# nrf7140_application register map
Vendor: Nordic Semiconductor; Series: nRF71; File version: 1
CPU: CM33 r0p4, little endian, MPU, FPU, 3 interrupt priority bits, 480 interrupts, 8 SAU regions
Registers are 32-bit, read-write, reset 0x0 unless marked. A register's access mark holds for its fields unless they carry their own. Offsets are from the block's base; [hi:lo] are bit positions; lines under a group give offsets from that group; {n}, {i} and the like mark numbered series; 'fields as' and 'values as' point back to an identical list.

## GLOBAL_SDCARD_NS — SD-Card and eMMC 0
Base 0x4F8C9000
Same registers: GLOBAL_SDCARD_S 0x5F8C9000
0x500 ENABLE — Enable the SDCARD peripheral
  [0] ENABLE — Enable or disable SDCARD
    0=Disabled (Disable SDCARD); 1=Enabled (Enable SDCARD)
0x600 CORE group — Unspecified
  0x00 SDMASAR — This register is used to configure a 32-bit Block Count or an SDMA System Address based on the Host Version 4 Enable bit in the Host Control 2 register. This register is applicable for both SD and eMMC modes.
    [31:0] BLOCKCNTSDMASA — 32-bit Block Count (SDMA System Address)
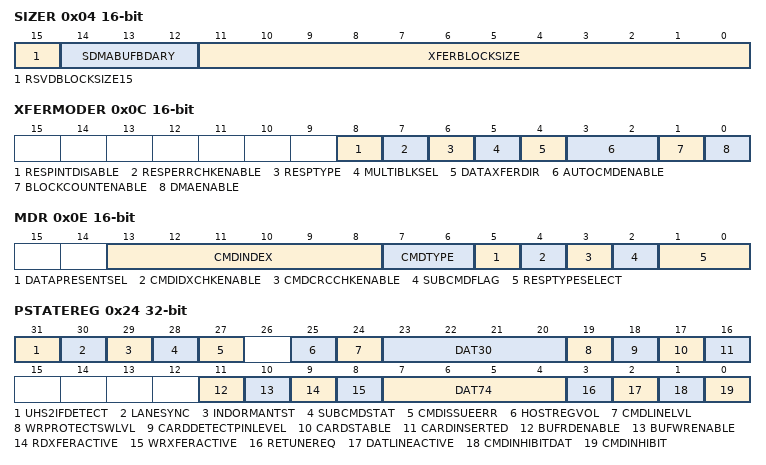
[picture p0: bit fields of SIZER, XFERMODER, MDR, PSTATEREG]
  0x04 SIZER 16-bit — This register is used to configure an SDMA buffer boundary and the number of bytes in a data block. This register is applicable for both SD and eMMC modes.
    [15] RSVDBLOCKSIZE15 ro — This bit of the BLOCKSIZE_R register is reserved. It always returns 0.
    [14:12] SDMABUFBDARY — SDMA Buffer Boundary
      0=BYTES4K (4K bytes SDMA Buffer Boundary); 1=BYTES8K (8K bytes SDMA Buffer Boundary); 2=BYTES16K (16K bytes SDMA Buffer Boundary); 3=BYTES32K (32K bytes SDMA Buffer Boundary); 4=BYTES64K (64K bytes SDMA Buffer Boundary); 5=BYTES128K (128K bytes SDMA Buffer Boundary); 6=BYTES256K (256K bytes SDMA Buffer Boundary); 7=BYTES512K (512K bytes SDMA Buffer Boundary)
    [11:0] XFERBLOCKSIZE — Transfer Block Size
  0x06 UNTR 16-bit — This register is used to configure the number of data blocks. This register is applicable for both SD and eMMC modes.
    [15:0] BLOCKCNT — 16-bit Block Count
  0x08 ARGUMENTR — This register is used to configure the SD/eMMC command argument.
    [31:0] ARGUMENT — Command Argument
  0x0C XFERMODER 16-bit — This register is used to control the operation of data transfers for an SD/eMMC mode. The Host driver sets this register before issuing a command that transfers data.
    [8] RESPINTDISABLE
      0=ENABLED (Response Interrupt is enabled); 1=DISABLED (Response Interrupt is disabled)
    [7] RESPERRCHKENABLE
      0=DISABLED (Response Error Check is disabled); 1=ENABLED (Response Error Check is enabled)
    [6] RESPTYPE
      0=RESPR1 (R1 (Memory)); 1=RESPR5 (R5 (SDIO))
    [5] MULTIBLKSEL
      0=SINGLE (Single Block); 1=MULTI (Multiple Block)
    [4] DATAXFERDIR
      0=WRITE (Write (Host to Card)); 1=READ (Read (Card to Host))
    [3:2] AUTOCMDENABLE — Auto Command Enable
      0=AUTOCMDDISABLED (Auto Command Disabled); 1=AUTOCMD12ENABLED; 2=AUTOCMD23ENABLED; 3=AUTOCMDAUTOSEL (Auto CMD Auto Select)
    [1] BLOCKCOUNTENABLE
      0=DISABLED; 1=ENABLED
    [0] DMAENABLE
      0=DISABLED (No data transfer or Non-DMA data transfer); 1=ENABLED (DMA Data transfer)
  0x0E MDR 16-bit — This register is used to provide the information related to a command and a response packet. This register is applicable for an SD/eMMC mode.
    [13:8] CMDINDEX — Command Index
    [7:6] CMDTYPE — Command Type
      0=NORMALCMD; 1=SUSPENDCMD; 2=RESUMECMD; 3=ABORTCMD
    [5] DATAPRESENTSEL — Data Present Select
      0=NODATA (No Data Present); 1=DATA (Data Present)
    [4] CMDIDXCHKENABLE — Command Index Check Enable
      0=DISABLED; 1=ENABLED
    [3] CMDCRCCHKENABLE — Command CRC Check Enable
      0=DISABLED; 1=ENABLED
    [2] SUBCMDFLAG — Sub Command Flag
      0=MAIN (Main Command); 1=SUB (Sub Command)
    [1:0] RESPTYPESELECT — Response Type Select
      0=NORESP (No Response); 1=RESPLEN136 (Response Length 136); 2=RESPLEN48 (Response Length 48); 3=RESPLEN48B (Response Length 48; Check Busy after response)
  0x10 RESP01R — This register stores 39-08 bits of the Response Field for an SD/eMMC mode. The response for an SD/eMMC command can be a maximum of 128 bits. These 128 bits are segregated into four 32-bit registers: RESP01_R, RESP23_R, RESP45_R and RESP67_R.
    [31:0] RESP01 ro — Command Response
  0x14 RESP23R — This register stores 71-40 bits of the Response Field for an SD/eMMC mode. This register is used to store the response from the cards. The response can be a maximum of 128 bits. These 128 bits are segregated into four 32-bit
    [31:0] RESP23 ro — Command Response
  0x18 RESP45R — This register stores 103-72 bits of the Response Field for an SD/eMMC mode. The response for SD/eMMC command can be a maximum of 128 bits. These 128 bits are segregated into four 32-bit registers: RESP01_R, RESP23_R, RESP45_R and RESP67_R.
    [31:0] RESP45 ro — Command Response
  0x1C RESP67R — This register stores 135-104 bits of the Response Field for an SD/eMMC mode. The SD/eMMC response can be a maximum of 128 bits. These 128 bits are segregated into four 32-bit registers: RESP01_R, RESP23_R, RESP45_R and RESP67_R.
    [31:0] RESP67 ro — Command Response
  0x20 UFDATAR — This register is used to access the packet buffer. This register is applicable for an SD/eMMC/UHS-II mode.
    [31:0] BUFDATA — Buffer Data
  0x24 PSTATEREG — This register indicates the present status of the Host Controller. This register is applicable for an SD/eMMC/UHS-II mode.
    [31] UHS2IFDETECT ro — UHS-II Interface Detection
      0=FALSE (UHS-II interface is not detected); 1=TRUE (UHS-II interface is detected)
    [30] LANESYNC ro
      0=FALSE (UHS-II PHY is not initialized); 1=TRUE (UHS-II PHY is initialized)
    [29] INDORMANTST ro
      0=FALSE (Not in DORMANT state); 1=TRUE (In DORMANT state)
    [28] SUBCMDSTAT ro
      0=FALSE (Main Command Status); 1=TRUE (Sub Command Status)
    [27] CMDISSUEERR ro — Command Not Issued by Error
      0=FALSE (No error for issuing a command); 1=TRUE (Command cannot be issued)
    [25] HOSTREGVOL ro — Host Regulator Voltage Stable
      0=FALSE (Host Regulator Voltage is not stable); 1=TRUE (Host Regulator Voltage is stable)
    [24] CMDLINELVL ro — Command-Line Signal Level
    [23:20] DAT30 ro — DAT[3:0] Line Signal Level
    [19] WRPROTECTSWLVL ro — Write Protect Switch Pin Level
      0=FALSE (Write protected); 1=TRUE (Write enabled)
    [18] CARDDETECTPINLEVEL ro
      0=FALSE (No card present); 1=TRUE (Card Present)
    [17] CARDSTABLE ro
      0=FALSE (Reset or Debouncing); 1=TRUE (No Card or Inserted)
    [16] CARDINSERTED ro
      0=FALSE (Reset, Debouncing, or No card); 1=TRUE (Card Inserted)
    [11] BUFRDENABLE ro — Buffer Read Enable
      0=DISABLED (Read disable); 1=ENABLED (Read enable)
    [10] BUFWRENABLE ro — Buffer Write Enable
      0=DISABLED (Write disable); 1=ENABLED (Write enable)
    [9] RDXFERACTIVE ro — Read Transfer Active
      0=INACTIVE (No valid data); 1=ACTIVE (Transferring data)
    [8] WRXFERACTIVE ro
      0=INACTIVE (No valid data); 1=ACTIVE (Transferring data)
    [7:4] DAT74 ro — DAT[7:4] Line Signal Level
    [3] RETUNEREQ ro — Re-Tuning Request
    [2] DATLINEACTIVE ro — DAT Line Active (SD/eMMC Mode only)
      0=INACTIVE (DAT Line Inactive); 1=ACTIVE (DAT Line Active)
    [1] CMDINHIBITDAT ro — Command Inhibit (DAT)
      0=READY (Can issue command which used DAT line); 1=NOTREADY (Cannot issue command which used DAT line)
    [0] CMDINHIBIT ro — Command Inhibit (CMD)
      0=READY (Host Controller is ready to issue a command); 1=NOTREADY (Host Controller is not ready to issue a command)
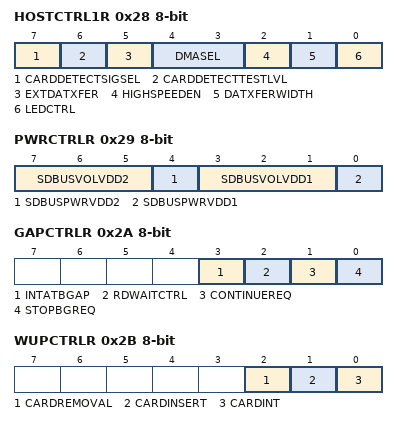
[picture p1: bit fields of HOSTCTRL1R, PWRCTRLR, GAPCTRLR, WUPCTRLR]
  0x28 HOSTCTRL1R 8-bit — Unspecified
    [7] CARDDETECTSIGSEL — Card Detect Signal Selection
      0=SDCDPIN (SDCD# (card_detect_n signal) is selected (for normal use)); 1=CARDDTTESTLEVEL (Card Detect Test Level is selected (for test purpose))
    [6] CARDDETECTTESTLVL — Card Detect Test Level
      0=NOCARD; 1=CARDINSERTED
    [5] EXTDATXFER
      0=DEFAULT (Bus Width is selected by the Data Transfer Width); 1=EIGHTBIT (8-bit Bus Width)
    [4:3] DMASEL
      0=SDMA (SDMA is selected); 1=RSVDBIT (Unspecified); 2=ADMA2 (ADMA2 is selected); 3=ADMA23 (ADMA2 or ADMA3 is selected)
    [2] HIGHSPEEDEN — High Speed Enable (SD/eMMC Mode only)
      0=NORMALSPEED (Normal Speed mode); 1=HIGHSPEED (High Speed mode)
    [1] DATXFERWIDTH — Data Transfer Width
      0=ONEBIT (1-bit mode); 1=FOURBIT (4-bit mode)
    [0] LEDCTRL — LED Control
      0=OFF (LED off); 1=ON (LED on)
  0x29 PWRCTRLR 8-bit — This register is used to control the bus power for the Card. This register is applicable for an SD, eMMC, and UHS-II modes.
    [7:5] SDBUSVOLVDD2
      0=NOVDD2 (VDD2 Not Supported); 1=RSVD1 (Unspecified); 2=RSVD2 (Unspecified); 3=RSVD3 (Unspecified); 4=V12 (Reserved for 1.2V); 5=V18 (1.8V); 6=NOTUSED6; 7=NOTUSED7
    [4] SDBUSPWRVDD2
      0=OFF (Power off); 1=ON (Power on)
    [3:1] SDBUSVOLVDD1
      {v}=RSVD{v} (Unspecified) (v=0..4); 5=V18 (1.8V (Typ.) for Embedded); 6=V30 (3.0V (Typ.)); 7=V33 (3.3V (Typ.))
    [0] SDBUSPWRVDD1
      0=OFF (Power off); 1=ON (Power on)
  0x2A GAPCTRLR 8-bit — This register is used by the host driver to control any operation related to Block Gap. This register is applicable for an SD/eMMC/UHS-II mode.
    [3] INTATBGAP
      0=DISABLE (Disabled); 1=ENABLE (Enabled)
    [2] RDWAITCTRL
      0=DISABLE (Disable Read Wait Control); 1=ENABLE (Enable Read Wait Control)
    [1] CONTINUEREQ
      0=NOAFFECT; 1=RESTART
    [0] STOPBGREQ
      0=XFER (Transfer); 1=STOP
  0x2B WUPCTRLR 8-bit — Unspecified
    [all] fields
      0=DISABLED; 1=ENABLED
    [2] CARDREMOVAL
    [1] CARDINSERT
    [0] CARDINT
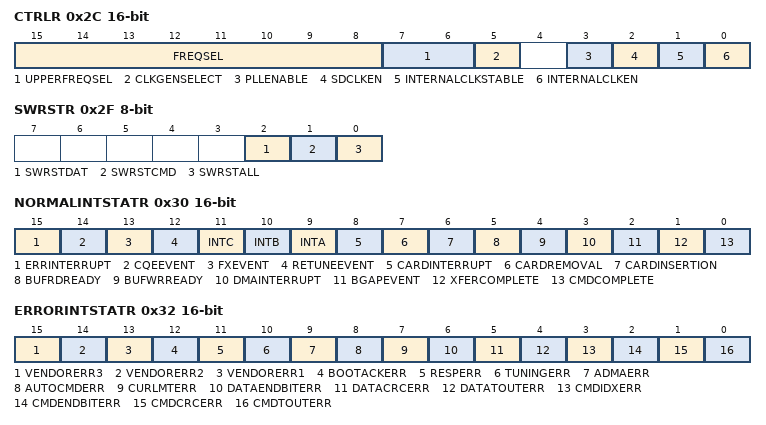
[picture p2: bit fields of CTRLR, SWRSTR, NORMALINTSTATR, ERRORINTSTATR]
  0x2C CTRLR 16-bit — Unspecified
    [15:8] FREQSEL
    [7:6] UPPERFREQSEL
    [5] CLKGENSELECT
      0=FALSE (Divided Clock Mode); 1=TRUE (Programmable Clock Mode)
    [3] PLLENABLE
      0=FALSE (PLL is in low power mode); 1=TRUE (PLL is enabled)
    [2] SDCLKEN
      0=FALSE (Disable providing SDCLK/RCLK); 1=TRUE (Enable providing SDCLK/RCLK)
    [1] INTERNALCLKSTABLE ro
      0=FALSE (Not Ready); 1=TRUE (Ready)
    [0] INTERNALCLKEN
      0=FALSE (Stop); 1=TRUE (Oscillate)
  0x2E TOUTCTRLR 8-bit — This register is used to set the Data Timeout Counter value for an SD/eMMC mode according to the timer clock defined by the Capabilities register, while
    [3:0] TOUTCNT
  0x2F SWRSTR 8-bit — This register is used to generate a reset pulse by writing 1 to each bit of this register. After completing the reset, the Host Controller clears each bit. As it takes some time to complete a software reset, the Host Driver confirms that these bits are 0. This register is applicable for an SD/eMMC/UHS-II mode.
    [all] fields
      0=FALSE (Work); 1=TRUE (Reset)
    [2] SWRSTDAT
    [1] SWRSTCMD
    [0] SWRSTALL — Software Reset For All
  0x30 NORMALINTSTATR 16-bit — Unspecified
    [15] ERRINTERRUPT ro
      0=FALSE (No Error); 1=TRUE (Error)
    [14] CQEEVENT
      0=FALSE (No Event); 1=TRUE (Command Queuing Event is detected)
    [13] FXEVENT ro
      0=FALSE (No Event); 1=TRUE (FX Event is detected)
    [12] RETUNEEVENT ro
    [11] INTC ro
    [10] INTB ro
    [9] INTA ro
    [8] CARDINTERRUPT ro
      0=FALSE (No Card Interrupt); 1=TRUE (Generate Card Interrupt)
    [7] CARDREMOVAL
      0=FALSE (Card state stable or Debouncing); 1=TRUE (Card Removed)
    [6] CARDINSERTION
      0=FALSE (Card state stable or Debouncing); 1=TRUE (Card Inserted)
    [5] BUFRDREADY
      0=FALSE (Not ready to read buffer); 1=TRUE (Ready to read buffer)
    [4] BUFWRREADY
      0=FALSE (Not ready to write buffer); 1=TRUE (Ready to write buffer)
    [3] DMAINTERRUPT
      0=FALSE (No DMA Interrupt); 1=TRUE (DMA Interrupt is generated)
    [2] BGAPEVENT
      0=FALSE (No Block Gap Event); 1=TRUE (Transaction stopped at block gap)
    [1] XFERCOMPLETE
      0=FALSE (Not complete); 1=TRUE (Command execution is completed)
    [0] CMDCOMPLETE
      0=FALSE (No command complete); 1=TRUE (Command Complete)
  0x32 ERRORINTSTATR 16-bit — This register enables an interrupt when the Error Interrupt Status Enable is enabled and at least one of the statuses is set to 1. Writing to 1 clears the bit
    [15] VENDORERR3 — This bit (VENDOR_ERR3) of the ERROR_INT_STAT_R register is reserved. It always returns 0.
    [14] VENDORERR2 — This bit (VENDOR_ERR2) of the ERROR_INT_STAT_R register is reserved. It always returns 0.
    [13] VENDORERR1 — This bit (VENDOR_ERR1) of the ERROR_INT_STAT_R register is reserved. It always returns 0.
    [12] BOOTACKERR — Boot Acknowledgement Error
      0=FALSE (No error); 1=TRUE (Error)
    [11] RESPERR — Response Error
      0=FALSE (No error); 1=TRUE (Error)
    [10] TUNINGERR — Tuning Error
      0=FALSE (No error); 1=TRUE (Error)
    [9] ADMAERR — ADMA Error
      0=FALSE (No error); 1=TRUE (Error)
    [8] AUTOCMDERR — Auto CMD Error
      0=FALSE (No error); 1=TRUE (Error)
    [7] CURLMTERR — Current Limit Error
      0=FALSE (No error); 1=TRUE (Power Fail)
    [6] DATAENDBITERR — Data End Bit Error
      0=FALSE (No error); 1=TRUE (Error)
    [5] DATACRCERR — Data CRC Error
      0=FALSE (No error); 1=TRUE (Error)
    [4] DATATOUTERR — Data Timeout Error
      0=FALSE (No error); 1=TRUE (Time out)
    [3] CMDIDXERR — Command Index Error
      0=FALSE (No error); 1=TRUE (Error)
    [2] CMDENDBITERR — Command End Bit Error
      0=FALSE (No error); 1=TRUE (End Bit error generated)
    [1] CMDCRCERR — Command CRC Error
      0=FALSE (No error); 1=TRUE (CRC error generated)
    [0] CMDTOUTERR — Command Timeout Error
      0=FALSE (No error); 1=TRUE (Time out)
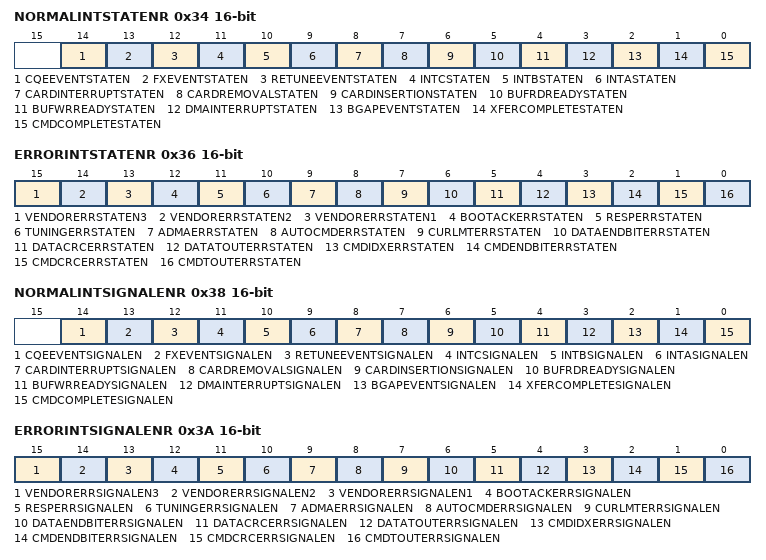
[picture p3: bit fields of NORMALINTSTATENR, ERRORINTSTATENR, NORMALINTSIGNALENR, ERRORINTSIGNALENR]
  0x34 NORMALINTSTATENR 16-bit — Unspecified
    [all] fields
      0=FALSE (Masked); 1=TRUE (Enabled)
    [14] CQEEVENTSTATEN
    [13] FXEVENTSTATEN
    [12] RETUNEEVENTSTATEN
    [11] INTCSTATEN
    [10] INTBSTATEN
    [9] INTASTATEN
    [8] CARDINTERRUPTSTATEN
    [7] CARDREMOVALSTATEN
    [6] CARDINSERTIONSTATEN
    [5] BUFRDREADYSTATEN
    [4] BUFWRREADYSTATEN
    [3] DMAINTERRUPTSTATEN
    [2] BGAPEVENTSTATEN
    [1] XFERCOMPLETESTATEN
    [0] CMDCOMPLETESTATEN
  0x36 ERRORINTSTATENR 16-bit — Unspecified
    [all] fields
      0=FALSE (Masked); 1=TRUE (Enabled)
    [15] VENDORERRSTATEN3
    [14] VENDORERRSTATEN2
    [13] VENDORERRSTATEN1
    [12] BOOTACKERRSTATEN
    [11] RESPERRSTATEN
    [10] TUNINGERRSTATEN
    [9] ADMAERRSTATEN
    [8] AUTOCMDERRSTATEN
    [7] CURLMTERRSTATEN
    [6] DATAENDBITERRSTATEN
    [5] DATACRCERRSTATEN
    [4] DATATOUTERRSTATEN
    [3] CMDIDXERRSTATEN
    [2] CMDENDBITERRSTATEN
    [1] CMDCRCERRSTATEN
    [0] CMDTOUTERRSTATEN
  0x38 NORMALINTSIGNALENR 16-bit — Unspecified
    [all] fields
      0=FALSE (Masked); 1=TRUE (Enabled)
    [14] CQEEVENTSIGNALEN
    [13] FXEVENTSIGNALEN
    [12] RETUNEEVENTSIGNALEN
    [11] INTCSIGNALEN
    [10] INTBSIGNALEN
    [9] INTASIGNALEN
    [8] CARDINTERRUPTSIGNALEN
    [7] CARDREMOVALSIGNALEN
    [6] CARDINSERTIONSIGNALEN
    [5] BUFRDREADYSIGNALEN
    [4] BUFWRREADYSIGNALEN
    [3] DMAINTERRUPTSIGNALEN
    [2] BGAPEVENTSIGNALEN
    [1] XFERCOMPLETESIGNALEN
    [0] CMDCOMPLETESIGNALEN
  0x3A ERRORINTSIGNALENR 16-bit — Unspecified
    [15] VENDORERRSIGNALEN3
      0=FALSE (Masked); 1=TRUE (Enabled)
    [14] VENDORERRSIGNALEN2
      0=FALSE (Masked); 1=TRUE (Enabled)
    [13] VENDORERRSIGNALEN1
      0=FALSE (Masked); 1=TRUE (Enabled)
    [12] BOOTACKERRSIGNALEN
      0=FALSE (Masked); 1=TRUE (Enabled)
    [11] RESPERRSIGNALEN
      0=FALSE (Masked); 1=TRUE (Enabled)
    [10] TUNINGERRSIGNALEN
      0=FALSE (Masked); 1=TRUE (Enabled)
    [9] ADMAERRSIGNALEN
      0=FALSE (Masked); 1=TRUE (Enabled)
    [8] AUTOCMDERRSIGNALEN
      0=FALSE (Masked); 1=TRUE (Enabled)
    [7] CURLMTERRSIGNALEN
      0=FALSE (Masked); 1=TRUE (Enabled)
    [6] DATAENDBITERRSIGNALEN
      0=FALSE (Masked); 1=TRUE (Enabled)
    [5] DATACRCERRSIGNALEN
      0=FALSE (Masked); 1=TRUE (Enabled)
    [4] DATATOUTERRSIGNALEN
      0=FALSE (Masked); 1=TRUE (Enabled)
    [3] CMDIDXERRSIGNALEN
      0=FALSE (No error); 1=TRUE (Error)
    [2] CMDENDBITERRSIGNALEN
      0=FALSE (Masked); 1=TRUE (Enabled)
    [1] CMDCRCERRSIGNALEN
      0=FALSE (Masked); 1=TRUE (Enabled)
    [0] CMDTOUTERRSIGNALEN
      0=FALSE (Masked); 1=TRUE (Enabled)
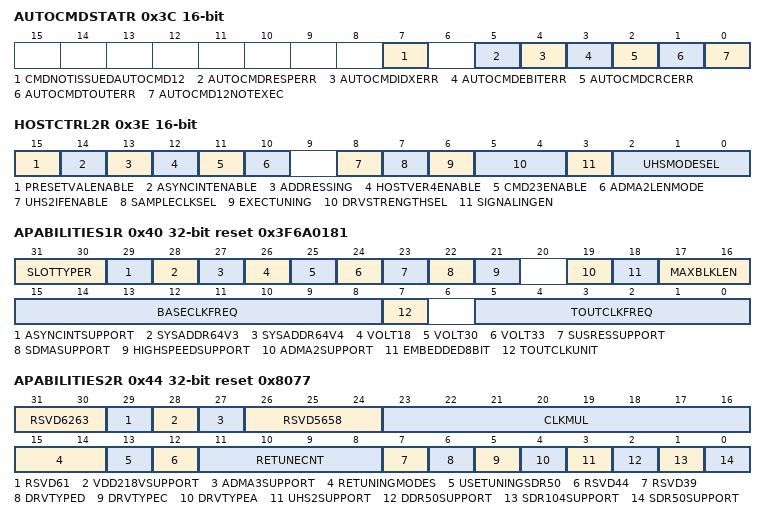
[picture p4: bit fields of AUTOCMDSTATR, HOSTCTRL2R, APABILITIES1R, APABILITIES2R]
  0x3C AUTOCMDSTATR 16-bit — Unspecified
    [7] CMDNOTISSUEDAUTOCMD12 ro
      0=FALSE (No Error); 1=TRUE (Not Issued)
    [5] AUTOCMDRESPERR ro
      0=FALSE (No Error); 1=TRUE (Error)
    [4] AUTOCMDIDXERR ro
      0=FALSE (No Error); 1=TRUE (Error)
    [3] AUTOCMDEBITERR ro
      0=FALSE (No Error); 1=TRUE (End Bit Error Generated)
    [2] AUTOCMDCRCERR ro
      0=FALSE (No Error); 1=TRUE (CRC Error Generated)
    [1] AUTOCMDTOUTERR ro
      0=FALSE (No Error); 1=TRUE (Time out)
    [0] AUTOCMD12NOTEXEC ro
      0=FALSE (Executed); 1=TRUE (Not Executed)
  0x3E HOSTCTRL2R 16-bit — Unspecified
    [15] PRESETVALENABLE
      0=FALSE (SDCLK and Driver Strength are controlled by Host Driver); 1=TRUE (Automatic Selection by Preset Value are Enabled)
    [14] ASYNCINTENABLE
      0=FALSE (Disabled); 1=TRUE (Enabled)
    [13] ADDRESSING
      0=FALSE (32 bits addressing); 1=TRUE (64 bits addressing)
    [12] HOSTVER4ENABLE
      0=FALSE (Version 3.00 compatible mode); 1=TRUE (Version 4 mode)
    [11] CMD23ENABLE
      0=FALSE (Auto CMD23 is disabled); 1=TRUE (Auto CMD23 is enabled)
    [10] ADMA2LENMODE
      0=FALSE (16-bit Data Length Mode); 1=TRUE (26-bit Data Length Mode)
    [8] UHS2IFENABLE
      0=FALSE (SD/eMMC Interface Enabled); 1=TRUE (UHS-II Interface Enabled)
    [7] SAMPLECLKSEL
      0=FALSE (Fixed clock is used to sample data); 1=TRUE (Tuned clock is used to sample data)
    [6] EXECTUNING
      0=FALSE (Not Tuned or Tuning completed); 1=TRUE (Execute Tuning)
    [5:4] DRVSTRENGTHSEL
      0=TYPEB (Driver TYPEB is selected); 1=TYPEA (Driver TYPEA is selected); 2=TYPEC (Driver TYPEC is selected); 3=TYPED (Driver TYPED is selected)
    [3] SIGNALINGEN
      0=V33 (3.3V Signalling); 1=V18 (1.8V Signalling)
    [2:0] UHSMODESEL
      0=SDR12 (SDR12/Legacy); 1=SDR25 (SDR25/High Speed SDR); 2=SDR50; 3=SDR104 (SDR104/HS200); 4=DDR50 (DDR50/High Speed DDR); 5=RSVD5 (Unspecified); 6=RSVD6 (Unspecified); 7=UHS2 (UHS-II/HS400)
  0x40 APABILITIES1R reset 0x3F6A0181 — Unspecified
    [31:30] SLOTTYPER ro
      0=REMOVABLESLOT (Removable Card Slot); 1=EMBEDDEDSLOT (Embedded Slot for one Device); 2=SHAREDSLOT (Shared Bus Slot (SD mode)); 3=UHS2EMBEDDEDSLOT (UHS-II Multiple Embedded Devices)
    [29] ASYNCINTSUPPORT ro
      0=FALSE (Asynchronous Interrupt Not Supported); 1=TRUE (Asynchronous Interrupt Supported)
    [28] SYSADDR64V3 ro
      0=FALSE (64-bit System Address for V3 is Not Supported); 1=TRUE (64-bit System Address for V3 is Supported)
    [27] SYSADDR64V4 ro
      0=FALSE (64-bit System Address for V4 is Not Supported); 1=TRUE (64-bit System Address for V4 is Supported)
    [26] VOLT18 ro
      0=FALSE (1.8V Not Supported); 1=TRUE (1.8V Supported)
    [25] VOLT30 ro
      0=FALSE (SD 3.0V or Embedded 1.2V Not Supported); 1=TRUE (SD 3.0V or Embedded Supported)
    [24] VOLT33 ro
      0=FALSE (3.3V Not Supported); 1=TRUE (3.3V Supported)
    [23] SUSRESSUPPORT ro
      0=FALSE (Not Supported); 1=TRUE (Supported)
    [22] SDMASUPPORT ro
      0=FALSE (SDMA not Supported); 1=TRUE (SDMA Supported)
    [21] HIGHSPEEDSUPPORT ro
      0=FALSE (High Speed not Supported); 1=TRUE (High Speed Supported)
    [19] ADMA2SUPPORT ro
      0=FALSE (ADMA2 not Supported); 1=TRUE (ADMA2 Supported)
    [18] EMBEDDED8BIT ro
      0=FALSE (8-bit Bus Width not Supported); 1=TRUE (8-bit Bus Width Supported)
    [17:16] MAXBLKLEN ro
      0=ZERO (512 Byte); 1=ONE (1024 Byte); 2=TWO (2048 Byte); 3=THREE (Unspecified)
    [15:8] BASECLKFREQ ro
    [7] TOUTCLKUNIT ro
      0=KHZ; 1=MHZ
    [5:0] TOUTCLKFREQ ro
  0x44 APABILITIES2R reset 0x8077 — Unspecified
    [31:30] RSVD6263 ro — These bits (RSVD_62_63) of the CAPABILITIES2_R register are reserved bits. They always return 0.
    [29] RSVD61 ro — This bit (RSVD_61) of the CAPABILITIES2_R register is reserved. It always returns 0.
    [28] VDD218VSUPPORT ro — 1.8V VDD2 Support
      0=FALSE (1.8V VDD2 is not Supported); 1=TRUE (1.8V VDD2 is Supported)
    [27] ADMA3SUPPORT ro
      0=FALSE (ADMA3 not Supported); 1=TRUE (ADMA3 Supported)
    [26:24] RSVD5658 ro — These bits (RSVD_56_58) of the CAPABILITIES2_R register are reserved. They always return 0.
    [23:16] CLKMUL ro
    [15:14] RETUNINGMODES ro
      0=MODE1 (Timer); 1=MODE2 (Timer and Re-Tuning Request (Not supported)); 2=MODE3 (Auto Re-Tuning (for transfer)); 3=RSVDMODE (Unspecified)
    [13] USETUNINGSDR50 ro — Use Tuning for SDR50 (UHS-I only)
      0=ZERO (SDR50 does not require tuning); 1=ONE (SDR50 requires tuning)
    [12] RSVD44 ro — This bit (RSVD_44) of the CAPABILITIES2_R register is reserved. It always returns 0.
    [11:8] RETUNECNT ro
    [7] RSVD39 ro — This bit (RSVD_39) of the CAPABILITIES2_R register is reserved. It always returns 0.
    [6] DRVTYPED ro
      0=FALSE (Driver Type D is not supported); 1=TRUE (Driver Type D is supported)
    [5] DRVTYPEC ro
      0=FALSE (Driver Type C is not supported); 1=TRUE (Driver Type C is supported)
    [4] DRVTYPEA ro
      0=FALSE (Driver Type A is not supported); 1=TRUE (Driver Type A is supported)
    [3] UHS2SUPPORT ro
      0=FALSE (UHS-II is not supported); 1=TRUE (UHS-II is supported)
    [2] DDR50SUPPORT ro — DDR50 Support (UHS-I only)
      0=FALSE (DDR50 is not supported); 1=TRUE (DDR50 is supported)
    [1] SDR104SUPPORT ro
      0=FALSE (SDR104 is not supported); 1=TRUE (SDR104 is supported)
    [0] SDR50SUPPORT ro
      0=FALSE (SDR50 is not supported); 1=TRUE (SDR50 is supported)
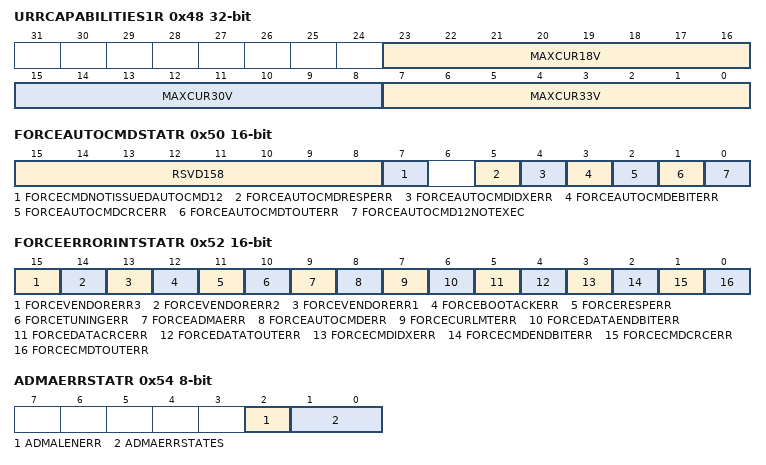
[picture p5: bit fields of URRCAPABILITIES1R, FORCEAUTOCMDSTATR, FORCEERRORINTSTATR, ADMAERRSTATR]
  0x48 URRCAPABILITIES1R — This register indicate the maximum current capability for each voltage, for VDD1. The value is meaningful if the Voltage Support is set in the Capabilities
    [23:16] MAXCUR18V ro — Maximum Current for 1.8V
    [15:8] MAXCUR30V ro — Maximum Current for 3.0V
    [7:0] MAXCUR33V ro — Maximum Current for 3.3V
  0x4C URRCAPABILITIES2R — This register indicates the maximum current capability for each voltage (for VDD2). The value is meaningful if Voltage Support is set in the Capabilities
    [7:0] MAXCURVDD218V ro — Maximum Current for 1.8V VDD2
  0x50 FORCEAUTOCMDSTATR 16-bit — Unspecified
    [15:8] RSVD158 ro — These bits of the FORCE_AUTO_CMD_STAT_R register are reserved. They always return 0.
    [7] FORCECMDNOTISSUEDAUTOCMD12 wo — Force Event for Command Not Issued By Auto CMD12 Error
      0=FALSE (Not Affected); 1=TRUE (Command Not Issued By Auto CMD12 Error Status is set)
    [5] FORCEAUTOCMDRESPERR wo
      0=FALSE (Not Affected); 1=TRUE (Auto CMD Response Error Status is set)
    [4] FORCEAUTOCMDIDXERR wo
      0=FALSE (Not Affected); 1=TRUE (Auto CMD Index Error Status is set)
    [3] FORCEAUTOCMDEBITERR wo
      0=FALSE (Not Affected); 1=TRUE (Auto CMD End Bit Error Status is set)
    [2] FORCEAUTOCMDCRCERR wo
      0=FALSE (Not Affected); 1=TRUE (Auto CMD CRC Error Status is set)
    [1] FORCEAUTOCMDTOUTERR wo
      0=FALSE (Not Affected); 1=TRUE (Auto CMD Timeout Error Status is set)
    [0] FORCEAUTOCMD12NOTEXEC wo
      0=FALSE (Not Affected); 1=TRUE (Auto CMD12 Not Executed Status is set)
  0x52 FORCEERRORINTSTATR 16-bit — This register is not physically implemented but is an address at which the Error Interrupt Status register can be written. The effect of a write to this
    [15] FORCEVENDORERR3 wo — This bit (FORCE_VENDOR_ERR3) of the FORCE_ERROR_INT_STAT_R register is reserved. It always returns 0.
    [14] FORCEVENDORERR2 wo — This bit (FORCE_VENDOR_ERR2) of the FORCE_ERROR_INT_STAT_R register is reserved. It always returns 0.
    [13] FORCEVENDORERR1 wo — This bit (FORCE_VENDOR_ERR1) of the FORCE_ERROR_INT_STAT_R register is reserved. It always returns 0.
    [12] FORCEBOOTACKERR wo — Force Event for Boot Ack error
      0=FALSE (Not Affected); 1=TRUE (Boot ack Error Status is set)
    [11] FORCERESPERR wo — Force Event for Response Error (SD Mode only)
      0=FALSE (Not Affected); 1=TRUE (Response Error Status is set)
    [10] FORCETUNINGERR wo — Force Event for Tuning Error (UHS-I Mode only)
      0=FALSE (Not Affected); 1=TRUE (Tuning Error Status is set)
    [9] FORCEADMAERR wo — Force Event for ADMA Error
      0=FALSE (Not Affected); 1=TRUE (ADMA Error Status is set)
    [8] FORCEAUTOCMDERR wo — Force Event for Auto CMD Error (SD/eMMC Mode only)
      0=FALSE (Not Affected); 1=TRUE (Auto CMD Error Status is set)
    [7] FORCECURLMTERR wo — Force Event for Current Limit Error
      0=FALSE (Not Affected); 1=TRUE (Current Limit Error Status is set)
    [6] FORCEDATAENDBITERR wo — Force Event for Data End Bit Error (SD/eMMC Mode only)
      0=FALSE (Not Affected); 1=TRUE (Data End Bit Error Status is set)
    [5] FORCEDATACRCERR wo — Force Event for Data CRC Error (SD/eMMC Mode only)
      0=FALSE (Not Affected); 1=TRUE (Data CRC Error Status is set)
    [4] FORCEDATATOUTERR wo — Force Event for Data Timeout Error (SD/eMMC Mode only)
      0=FALSE (Not Affected); 1=TRUE (Data Timeout Error Status is set)
    [3] FORCECMDIDXERR wo — Force Event for Command Index Error (SD/eMMC Mode only)
      0=FALSE (Not Affected); 1=TRUE (Command Index Error Status is set)
    [2] FORCECMDENDBITERR wo — Force Event for Command End Bit Error (SD/eMMC Mode only)
      0=FALSE (Not Affected); 1=TRUE (Command End Bit Error Status is set)
    [1] FORCECMDCRCERR wo — Force Event for Command CRC Error (SD/eMMC Mode only)
      0=FALSE (Not Affected); 1=TRUE (Command CRC Error Status is set)
    [0] FORCECMDTOUTERR wo — Force Event for Command Timeout Error (SD/eMMC Mode only)
      0=FALSE (Not Affected); 1=TRUE (Command Timeout Error Status is set)
  0x54 ADMAERRSTATR 8-bit — Unspecified
    [2] ADMALENERR ro
      0=NOERR (No Error); 1=ERROR
    [1:0] ADMAERRSTATES ro
      0=STSTOP (Stop DMA - SYS_ADR register points to a location next to the error descriptor); 1=STFDS (Fetch Descriptor - SYS_ADR register points to the error descriptor); 2=UNUSED (Never set this state); 3=STTFR (Transfer Data - SYS_ADR register points to a location next to the error descriptor)
  0x58 ADMASALOWR — Unspecified
    [31:0] ADMASALOW — ADMA System Address
  0x5C ADMASAHIGHR — This register holds the upper 32-bit system address for the DMA transfer. This register is applicable for an SD/eMMC/UHS-II mode.
    [31:0] ADMASAHIGH
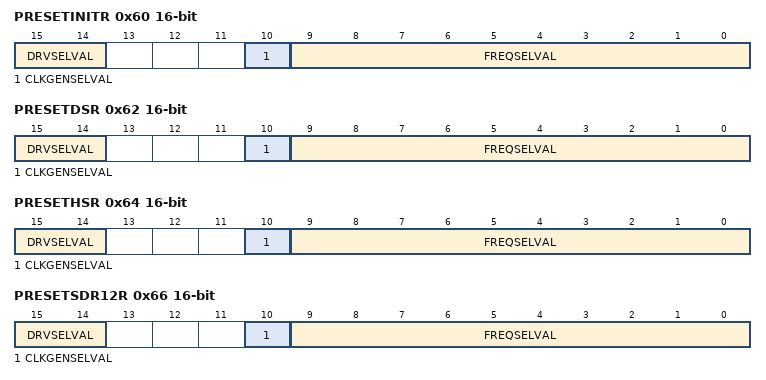
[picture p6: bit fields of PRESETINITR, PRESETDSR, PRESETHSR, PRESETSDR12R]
  0x60 PRESETINITR 16-bit — Unspecified
    [15:14] DRVSELVAL ro
      0=TYPEB (Driver Type B is selected); 1=TYPEA (Driver Type A is selected); 2=TYPEC (Driver Type C is selected); 3=TYPED (Driver Type D is selected)
    [10] CLKGENSELVAL ro
      0=FALSE (Host Controller Ver2.0 Compatible Clock Generator); 1=PROG (Programmable Clock Generator)
    [9:0] FREQSELVAL ro
  0x62 PRESETDSR 16-bit — Unspecified
    fields as CORE.PRESETINITR
  0x64 PRESETHSR 16-bit — Unspecified
    fields as CORE.PRESETINITR
  0x66 PRESETSDR12R 16-bit — Unspecified
    fields as CORE.PRESETINITR
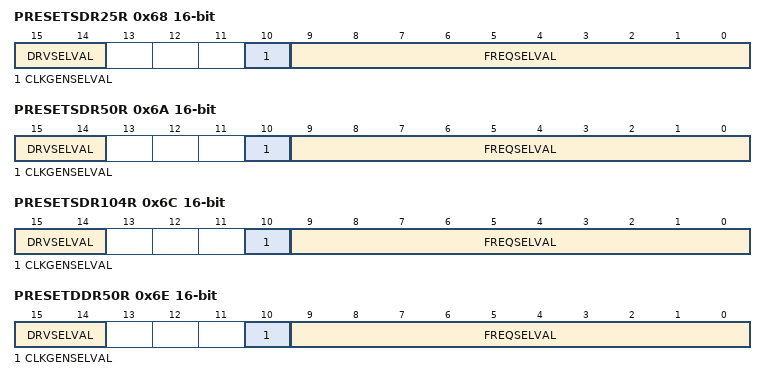
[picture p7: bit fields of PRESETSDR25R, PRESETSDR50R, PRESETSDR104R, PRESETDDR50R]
  0x68 PRESETSDR25R 16-bit — Unspecified
    fields as CORE.PRESETINITR
  0x6A PRESETSDR50R 16-bit — Unspecified
    fields as CORE.PRESETINITR
  0x6C PRESETSDR104R 16-bit — Unspecified
    fields as CORE.PRESETINITR
  0x6E PRESETDDR50R 16-bit — Unspecified
    [15:14] DRVSELVAL ro — Driver Strength Select Value
      values as CORE.PRESETINITR.DRVSELVAL
    [10] CLKGENSELVAL ro
      values as CORE.PRESETINITR.CLKGENSELVAL
    [9:0] FREQSELVAL ro
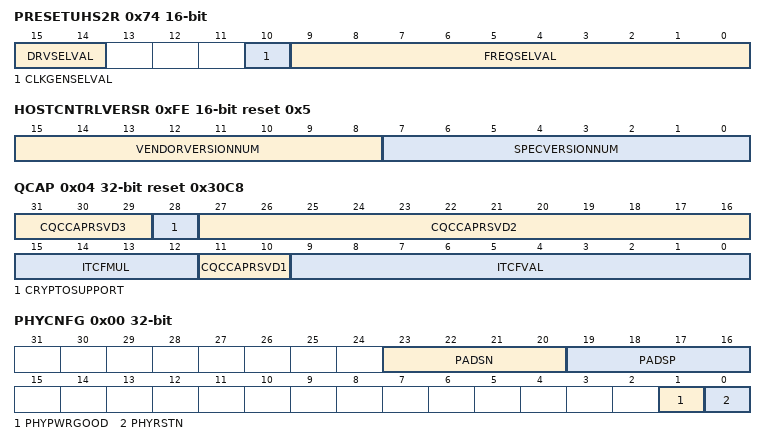
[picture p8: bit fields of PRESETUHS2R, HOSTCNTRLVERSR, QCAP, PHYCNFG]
  0x74 PRESETUHS2R 16-bit — This register is used to hold the preset value for UHS-II and HS400 speed modes in the SD and eMMC modes, respectively.
    [15:14] DRVSELVAL ro — Driver Strength Select Value
      values as CORE.PRESETINITR.DRVSELVAL
    [10] CLKGENSELVAL ro — Clock Generator Select Value
      values as CORE.PRESETINITR.CLKGENSELVAL
    [9:0] FREQSELVAL ro — SDCLK/RCLK Frequency Select Value
  0xE6 PEMBEDDEDCNTR 16-bit reset 0xF6C — This register points to the location of UHS-II embedded control registers.
    [11:0] REGOFFSETADDR ro — Offset Address of Embedded Control register.
  0xE8 PVENDORSPECIFICAREA 16-bit reset 0x500 — This register used as a pointer for the Vendor Specific Area 1.
    [11:0] REGOFFSETADDR ro — Base offset Address for Vendor-Specific registers.
  0xEA PVENDOR2SPECIFICAREA 16-bit reset 0x180 — This register is used as a pointer for the Vendor Specific Area 2.
    [15:0] REGOFFSETADDR ro — Base offset Address for Command Queuing registers.
  0xFC SLOTINTRSTATUSR 16-bit — This register indicates the Interrupt status of each slot.
    [7:0] INTRSLOT ro — Interrupt signal for each Slot
  0xFE HOSTCNTRLVERSR 16-bit reset 0x5 — This register is used to indicate the Host Controller Version number.
    [15:8] VENDORVERSIONNUM ro — Vendor Version Number
    [7:0] SPECVERSIONNUM ro — Specification Version Number
      0=VER100 (SD Host Controller Specification Version 1.00); 1=VER200 (SD Host Controller Specification Version 2.00); 2=VER300 (SD Host Controller Specification Version 3.00); 3=VER400 (SD Host Controller Specification Version 4.00); 4=VER410 (SD Host Controller Specification Version 4.10); 5=VER420 (SD Host Controller Specification Version 4.20)
0x780 VENDOR2 group — Unspecified
  0x04 QCAP reset 0x30C8 — This register indicates the capabilities of the command queuing engine.
    [31:29] CQCCAPRSVD3 ro — These bits [31:29] of the CQCAP register are reserved. They always return 0.
    [28] CRYPTOSUPPORT ro
      0=FALSE (Crypto not Supported); 1=TRUE (Crypto Supported)
    [27:16] CQCCAPRSVD2 ro — These bits [27:16] of the CQCAP register are reserved. They always return 0.
    [15:12] ITCFMUL ro — Internal Timer Clock Frequency Multiplier (ITCFMUL)
      0=CLK1KHZ (1KHz clock); 1=CLK10KHZ (10KHz clock); 2=CLK100KHZ (100KHz clock); 3=CLK1MHZ (1MHz clock); 4=CLK10MHZ (10MHz clock)
    [11:10] CQCCAPRSVD1 ro — These bits of the CQCAP register are reserved. They always return 0.
    [9:0] ITCFVAL ro — Internal Timer Clock Frequency Value (ITCFVAL)
0x900 PHY group — Unspecified
  0x00 PHYCNFG — SD/eMMC PHY general configuration register
    [23:20] PADSN — NMOS TX drive strength control. Common config for all for SD/eMMC Pads.
    [19:16] PADSP — PMOS TX drive strength control. Common config for all for SD/eMMC Pads.
    [1] PHYPWRGOOD ro — Phy's Power Good status is captured here. Ensure this is '1' before stating transactions.
    [0] PHYRSTN — Active-Low reset control for PHY, write '0' to reset PHY, Write '1' to deassert reset.
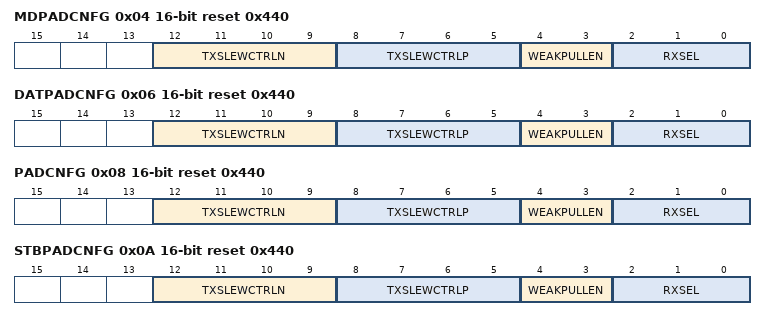
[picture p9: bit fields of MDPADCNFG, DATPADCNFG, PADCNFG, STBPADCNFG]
  0x04 MDPADCNFG 16-bit reset 0x440 — SD/eMMC PHY's Command/Response PAD settings are controlled here
    [12:9] TXSLEWCTRLN — Slew control for N-Type CMD Pad's TX
    [8:5] TXSLEWCTRLP — Slew control for P-Type CMD Pad's TX
    [4:3] WEAKPULLEN — Pull-up/Pul-down enable control for CMD PAD
      0=DISABLED (Pull-up and pull-down functionality disabled); 1=PULLUP (Weak pull up enabled); 2=PULLDOWN (Weak pull down enabled); 3=ILLEGAL (Should not be used)
    [2:0] RXSEL — Reciver type select for PAD. Controls the RXSEL value of SD/eMMC PHY CMD PAD
  0x06 DATPADCNFG 16-bit reset 0x440 — SD/eMMC PHY's Data PAD settings are controlled here. common settings for all data pads
    [12:9] TXSLEWCTRLN — Slew control for N-Type DATA Pad's TX
    [8:5] TXSLEWCTRLP — Slew control for P-Type DATA Pad's TX
    [4:3] WEAKPULLEN — Pull-up/Pull-down enable control for DATA PADs
      values as PHY.MDPADCNFG.WEAKPULLEN
    [2:0] RXSEL — Reciver type select for PAD. Controls the RXSEL value of SD/eMMC PHY DATA PADs
  0x08 PADCNFG 16-bit reset 0x440 — SD/eMMC PHY's CLK PAD settings are controlled here.
    [12:9] TXSLEWCTRLN — Slew control for N-Type CLK Pad's TX
    [8:5] TXSLEWCTRLP — Slew control for P-Type CLK Pad's TX
    [4:3] WEAKPULLEN — Pull-up/Pul-down enable control for CLK PAD
      values as PHY.MDPADCNFG.WEAKPULLEN
    [2:0] RXSEL — Reciver type select for PAD. Controls the RXSEL value of SD/eMMC PHY CLK PAD
  0x0A STBPADCNFG 16-bit reset 0x440 — SD/eMMC PHY's Strobe PAD settings are controlled here.
    [12:9] TXSLEWCTRLN — Slew control for N-Type Strobe Pad's TX
    [8:5] TXSLEWCTRLP — Slew control for P-Type Strobe Pad's TX
    [4:3] WEAKPULLEN — Pull-up/Pul-down enable control for STROBE PAD
      values as PHY.MDPADCNFG.WEAKPULLEN
    [2:0] RXSEL — Reciver type select for PAD. Controls the RXSEL value of SD/eMMC PHY STROBE PAD
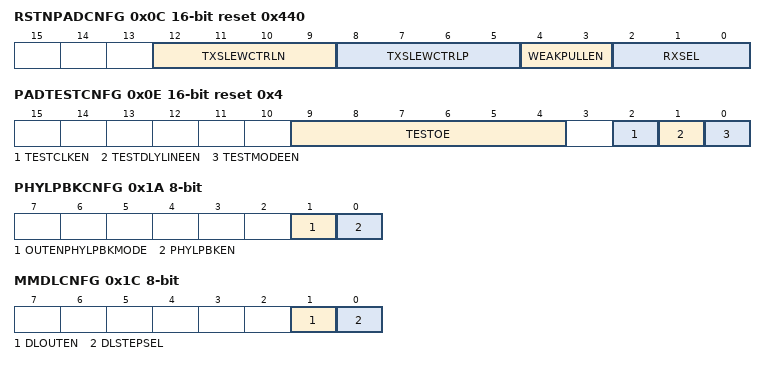
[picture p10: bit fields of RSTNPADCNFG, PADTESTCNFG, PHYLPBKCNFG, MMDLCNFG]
  0x0C RSTNPADCNFG 16-bit reset 0x440 — SD/eMMC PHY's RSTN PAD settings are controlled here.
    [12:9] TXSLEWCTRLN — Slew control for N-Type RST_N Pad's TX
    [8:5] TXSLEWCTRLP — Slew control for P-Type RST_N Pad's TX
    [4:3] WEAKPULLEN — Pull-up/Pul-down enable control for RST_N PAD(s)
      values as PHY.MDPADCNFG.WEAKPULLEN
    [2:0] RXSEL — Reciver type select for PAD. Controls the RXSEL value of SD/eMMC PHY RST_N PAD(s)
  0x0E PADTESTCNFG 16-bit reset 0x4 — PAD TEST Path and direction control
    [9:4] TESTOE — test interface OE control. Drive's PHY's itest_oe inputs.
    [2] TESTCLKEN — . While updating delay codes during testmode, this signal is used to gate the test clock. Functional interface is disabled.
      0=TESTCLKGATED (Gate the test clock); 1=TESTCLKENABLED (Test clock is enabled)
    [1] TESTDLYLINEEN — Test enable for delay line testing
      0=TESTDLYLINEDIS (Testing of Delay line disabled); 1=TESTDLYLINEEN (Testing of delay line enabled)
    [0] TESTMODEEN — enables test mode interface for all PADS. Functional interface is disabled.
      0=PADFUNCMODE (PAD's functional mode I/F is active); 1=PADTESTMODE (PAD's test mode interface is active)
  0x10 PADTESTOUT 16-bit — PAD TEST Path Data out, Drives itest_a input of SD/eMMC PHY
    [5:0] TESTDATAOUT — Data written here is reflected on corresponding itest_a. Indivitual bits are mapped to corresponding itest_a inputs of the PHY
  0x12 PADTESTIN 16-bit — PAD TEST Path Data in, reflects value of otest_y output of SD/eMMC PHY
    [5:0] TESTDATAIN ro — individual bits here capture data avaliable on corresponding otest_y output. should be used for DC test and low freq data patterns.
  0x18 PRBSCNFG 16-bit reset 0xFFFF — Register to configure PRBS engine
    [15:0] INITSEED — Value programmed here is used as SEED for PRBS engine
  0x1A PHYLPBKCNFG 8-bit — Register to setup loopback mode
    [1] OUTENPHYLPBKMODE — CMD/DATA output enable in PHY loopback mode
      0=OUTPUTDIS (CMD/DATA output is disable PHY Loopback mode); 1=OUTPUTEN (CMD/DATA output is enable PHY Loopback mode)
    [0] PHYLPBKEN — PHY Local loop back mode is enable
      0=PHYLPBKMODEDIS (Controller is not in PHY loopback mode); 1=PHYLPBKMODEEN (Controller is now in PHY Loopback mode)
  0x1C MMDLCNFG 8-bit — Config register to settings common to all DelayLines used in PHY
    [1] DLOUTEN — When '1' DL outputs can be sampled on PADs. Drives idlout_en for all PADs
      0=DLOUTDIS (DelayLine outputs on PAD disabled); 1=DLOUTEN (DelayLine outputs on PAD enabled)
    [0] DLSTEPSEL — DelayLine's per step delay selection, Drives PHY's idl_step input
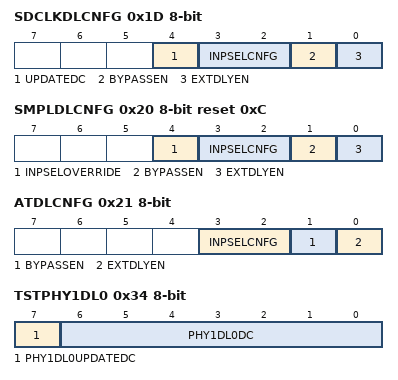
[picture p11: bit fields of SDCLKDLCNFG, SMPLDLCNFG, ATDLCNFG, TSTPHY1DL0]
  0x1D SDCLKDLCNFG 8-bit — Settings for SD/eMMC CLK DelayLine.
    [4] UPDATEDC — Prepares DealyLine for code update when '1'. Its recommended that this bit is 1 when SDCLKDL_DC is being written. Ensure this is '0' when not updating code.
      0=DLMODE (DelayLine output is enabled); 1=BYPASSMODE (output of DelayLine is DelayLine output active)
    [3:2] INPSELCNFG — Drives SD/eMMC CLK DelayLine's config input. Value here selects the input source to DelayLine
    [1] BYPASSEN — Drives SD/eMMC CLK DelayLine's bypassen input
      0=DLMODE (Delay line active mode); 1=BYPASSMODE (DelayLine is bypass mode)
    [0] EXTDLYEN — Drives SD/eMMC CLK DelayLine's extdlyen input
      0=DEFMODE (Delay line defaut range setting); 1=EXTDLMODE (DelayLine works with extended delay range setting)
  0x1E SDCLKDLD 8-bit — SD/eMMC CLK DelayLine Delay Code value
    [6:0] CCKDLDC — Drives SD/eMMC CLK DelayLine's Delay Code input.
  0x20 SMPLDLCNFG 8-bit reset 0xC — SD/eMMC cclk_rx DelayLine configuration settings
    [4] INPSELOVERRIDE — PHY's Sampling delay line config is controlled by controller using sample_cclk_sel,
    [3:2] INPSELCNFG — Drives CCLK_RX DelayLine's config input. Value here selects the input source to DelayLine
    [1] BYPASSEN — Drives CCLK_RX DelayLine's bypassen input
      values as PHY.SDCLKDLCNFG.BYPASSEN
    [0] EXTDLYEN — Drives CCLK_RX DelayLine's extdlyen input
      values as PHY.SDCLKDLCNFG.EXTDLYEN
  0x21 ATDLCNFG 8-bit — SD/eMMC drift_cclk_rx DelayLine configuration settings
    [3:2] INPSELCNFG — Drives drift_cclk_rx DelayLine's config input. Value here selects the input source to DelayLine
    [1] BYPASSEN — Drives drift_cclk_rx DelayLine's bypassen input
      values as PHY.SDCLKDLCNFG.BYPASSEN
    [0] EXTDLYEN — Drives drift_cclk_rx DelayLine's extdlyen input
      values as PHY.SDCLKDLCNFG.EXTDLYEN
  0x34 TSTPHY1DL0 8-bit — Settings for PHY1 Delay line 0 during testmode
    [7] PHY1DL0UPDATEDC — Delay code Update for PHY1 Delay Line0
      0=TSTDLMODE (DelayLine output is enabled); 1=TSTUPDATEMODE (During delay code update)
    [6:0] PHY1DL0DC — Delay code for PHY1 Delay Line0
0xB00 VENDOR1 group — Unspecified
  0x00 MSHCVERIDR reset 0x30323030 — This register reflects the current release number of DWC_mshc/DWC_mshc_lite.
    [31:0] MSHCVERID ro — Current release number
  0x04 MSHCVERTYPER reset 0x67612A2A — This register reflects the current release type of DWC_mshc/DWC_mshc_lite.
    [31:0] MSHCVERTYPE ro — Current release type
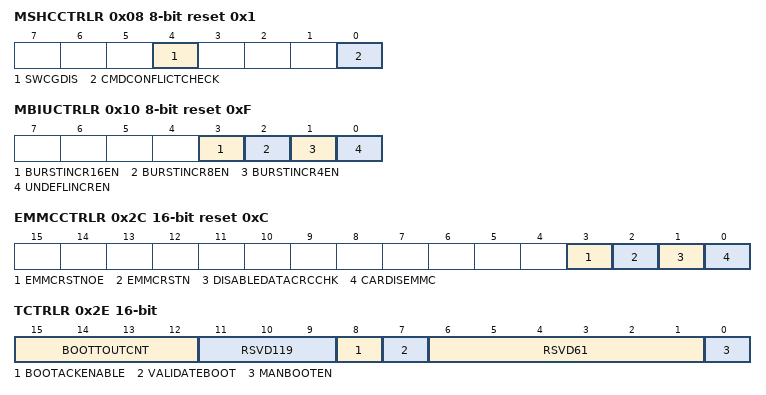
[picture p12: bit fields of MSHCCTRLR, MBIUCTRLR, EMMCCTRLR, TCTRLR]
  0x08 MSHCCTRLR 8-bit reset 0x1 — This register is used to control the operation of MSHC Host Controller.
    [4] SWCGDIS
      0=ENABLE (Internal clock gates are active and clock gating is controlled internally); 1=DISABLE (Internal clock gating is disabled, clocks are not gated internally)
    [0] CMDCONFLICTCHECK
      0=DISABLECMDCONFLICTCHK (Disable command conflict check); 1=CMDCONFLICTCHKLAT1 (Check for command conflict after 1 card clock cycle)
  0x10 MBIUCTRLR 8-bit reset 0xF — This register is used to select the valid burst types that the AHB Manager bus interface can generate.
    [3] BURSTINCR16EN — INCR16 Burst
      0=FALSE (AHB INCR16 burst type is not generated on Manager I/F); 1=TRUE (AHB INCR16 burst type can be generated on Manager I/F)
    [2] BURSTINCR8EN — INCR8 Burst
      0=FALSE (AHB INCR8 burst type is not generated on Manager I/F); 1=TRUE (AHB INCR8 burst type can be generated on Manager I/F)
    [1] BURSTINCR4EN — INCR4 Burst
      0=FALSE (AHB INCR4 burst type is not generated on Manager I/F); 1=TRUE (AHB INCR4 burst type can be generated on Manager I/F)
    [0] UNDEFLINCREN — Undefined INCR Burst
      0=FALSE (Undefined INCR type burst is the least preferred burst on AHB Manager I/F); 1=TRUE (Undefined INCR type burst is the most preferred burst on AHB Manager I/F)
  0x2C EMMCCTRLR 16-bit reset 0xC — This register is used to control the eMMC operation.
    [3] EMMCRSTNOE
      0=DISABLE (sd_rst_n_oe is 0); 1=ENABLE (sd_rst_n_oe is 1)
    [2] EMMCRSTN
      0=RSTASSERT (Reset to eMMC device asserted (active low)); 1=RSTDEASSERT (Reset to eMMC device is deasserted)
    [1] DISABLEDATACRCCHK
      0=ENABLE (DATA CRC check is enabled); 1=DISABLE (DATA CRC check is disabled)
    [0] CARDISEMMC
      0=NONEMMCCARD (Card connected to MSHC is a non-eMMC card); 1=EMMCCARD (Card connected to MSHC is an eMMC card)
  0x2E TCTRLR 16-bit — This register is used to control the eMMC Boot operation.
    [15:12] BOOTTOUTCNT
    [11:9] RSVD119 ro — These bits (RSVD_11_9) of the BOOT_CTRL_R register are reserved. They always return 0.
    [8] BOOTACKENABLE
      0=FALSE (Boot Ack disable); 1=TRUE (Boot Ack enable)
    [7] VALIDATEBOOT wo
      0=FALSE (Ignore Mandatory boot Enable bit); 1=TRUE (Validate Mandatory boot enable bit)
    [6:1] RSVD61 ro — These bits (RSVD _6_1) of the BOOT_CTRL_R register are reserved. They always return 0.
    [0] MANBOOTEN
      0=MANBOOTDIS (Mandatory boot disable); 1=MANBOOTEN (Mandatory boot enable)
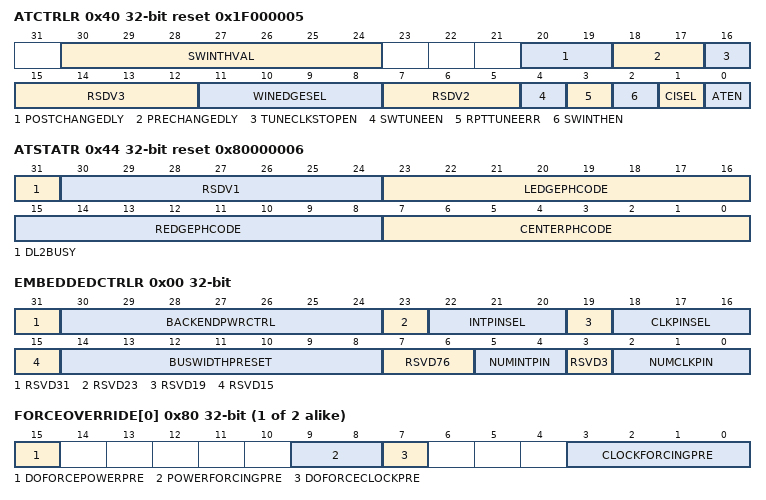
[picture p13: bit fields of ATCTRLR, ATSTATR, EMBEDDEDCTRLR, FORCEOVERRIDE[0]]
  0x40 ATCTRLR reset 0x1F000005 — This register controls some aspects of tuning and auto-tuning features. Do not program this register when HOST_CTRL2_R.SAMPLE_CLK_SEL is '1'
    [30:24] SWINTHVAL — Sampling window threshold value setting
    [20:19] POSTCHANGEDLY — Time taken for phase switching and stable clock output.
      {v}=LATENCYLT{v+1} (Less than {v+1}-cycle latency) (v=0..3)
    [18:17] PRECHANGEDLY — Maximum Latency specification between cclk_tx and cclk_rx.
      {v}=LATENCYLT{v+1} (Less than {v+1}-cycle latency) (v=0..3)
    [16] TUNECLKSTOPEN — Clock stopping control for Tuning and auto-tuning circuit.
      0=DISABLECLKSTOPPING (Clocks not stopped. PHY ensures glitch free phase switching.); 1=ENABLECLKSTOPPING (Clocks stopped during phase code change)
    [15:12] RSDV3 ro — These bits (RSVD3) of the AT_CTRL_R register are reserved. They always return 0.
    [11:8] WINEDGESEL — This field sets the phase for Left and Right edges for drift monitoring. [Left edge offset + Right edge offset] must not be less than total taps of delayLine.
    [7:5] RSDV2 ro — These bits (RSVD2) of the AT_CTRL_R register are reserved. They always return 0.
    [4] SWTUNEEN — This fields enables software-managed tuning flow.
      0=SWTUNINGDISABLE (Software-managed tuning disabled.); 1=SWTUNINGENABLE (Software-managed tuning enabled. AT_STAT_R.CENTER_PH_CODE Field is now writable.)
    [3] RPTTUNEERR — Framing errors are not generated when executing tuning. This debug bit allows users to report these errors.
      0=ERRORSDISABLED (Default mode where as per SD-HCI no errors are reported.); 1=DEBUGERRORS (Debug mode for reporting framing errors)
    [2] SWINTHEN — Sampling window Threshold enable
      0=LARGESTWINMODE (Tuning engine sweeps all taps and settles at the largest window); 1=THRESHOLDMODE (Tuning engine selects the first complete sampling window that meets the threshold set by SWIN_TH_VAL field)
    [1] CISEL — Selects the interval when the corrected center phase select code can be driven on tuning_cclk_sel output.
      0=WHENINBLKGAP (Driven in block gap interval); 1=WHENINIDLE (Driven at the end of the transfer)
    [0] ATEN — Setting this bit enables Auto tuning engine. This bit is enabled by default when core is configured with mode3 retuning support. Clear this bit to 0 when core is configured to have Mode3 re-tuning but SW wishes to disable mode3 re-tuning.
      0=ATDISABLE (AutoTuning is disabled); 1=ATENABLE (AutoTuning is enabled)
  0x44 ATSTATR reset 0x80000006 — Register to read the Center, Left and Right codes used by tuning and auto-tuning engines. Center code field is also used for software managed tuning.
    [31] DL2BUSY ro — Delay Line 2 busy indication. If this bit is set then it indicates that the cclk_rx delay line is in the process of delay code updation.
    [30:24] RSDV1 ro — These bits of the AT_STAT_R register are reserved. They always return 0.
    [23:16] LEDGEPHCODE ro — Left Edge Phase code. Reading this field returns the phase code value used by Auto-tuning engine to sample data on Left edge of sampling window.
    [15:8] REDGEPHCODE ro — Right Edge Phase code. Reading this field returns the phase code value used by Auto-tuning engine to sample data on Right edge of sampling window.
    [7:0] CENTERPHCODE — Centered Phase code. Reading this field returns the current value on tuning_cclk_sel output. Setting AT_CTRL_R.SW_TUNE_EN enables software to write to this field and its contents are reflected on tuning_cclk_sel.
0xC6C EMBEDDEDCONTR group — Unspecified
  0x00 EMBEDDEDCTRLR — This register controls the embedded device. When the Host Controller is connected to a removable device, this register is not used.
    [31] RSVD31 ro — This bit (RSVD_31) of the EMBEDDED_CTRL_R register is reserved. It always returns 0.
    [30:24] BACKENDPWRCTRL — Back-End Power Control (SD Mode)
    [23] RSVD23 ro — This bit (RSVD_23) of the EMBEDDED_CTRL_R register is reserved. It always returns 0.
    [22:20] INTPINSEL — Interrupt Pin Select
    [19] RSVD19 ro — This bit (RSVD_19) of the EMBEDDED_CTRL_R register is reserved. It always returns 0.
    [18:16] CLKPINSEL — Clock Pin Select (SD Mode)
    [15] RSVD15 ro — This bit (RSVD_15) of the EMBEDDED_CTRL_R register is reserved. It always returns 0.
    [14:8] BUSWIDTHPRESET ro — Bus Width Preset (SD Mode)
    [7:6] RSVD76 ro — These bits (RSVD_7_6) of the EMBEDDED_CTRL_R register are reserved. They always return 0.
    [5:4] NUMINTPIN ro — Number of Interrupt Input Pins
    [3] RSVD3 ro — This bit (RSVD_3) of the EMBEDDED_CTRL_R register is reserved. It always returns 0.
    [2:0] NUMCLKPIN ro — Number of Clock Pins (SD Mode)
0xF00 PCGCSLAVE group — Unspecified
  {0x0+4j} PENALTY[{j}] (j=0..1) reset 0xFFFFFFFC — Description collection: Penalty level for power/clock pair n. When FULL_PCP_ZERO feature is not supported, PENALTY[0] address overlaps the PENALTY0 address and register description for PENALTY[0] is not valid.
    [1:0] PENALTY — Penalty level
  0x00 PENALTY0 (alternate view of PENALTY[*]) — Penalty level for power/clock pair 0. The register description is valid only when FULL_PCP_ZERO feature is not supported
    [1:0] PENALTY ro — Penalty level
  {0x80+4j} FORCEOVERRIDE[{j}] (j=0..1) — Description collection: Force override of power/clock pair n.
    [15] DOFORCEPOWERPRE, [9:8] POWERFORCINGPRE, [7] DOFORCECLOCKPRE, [3:0] CLOCKFORCINGPRE
